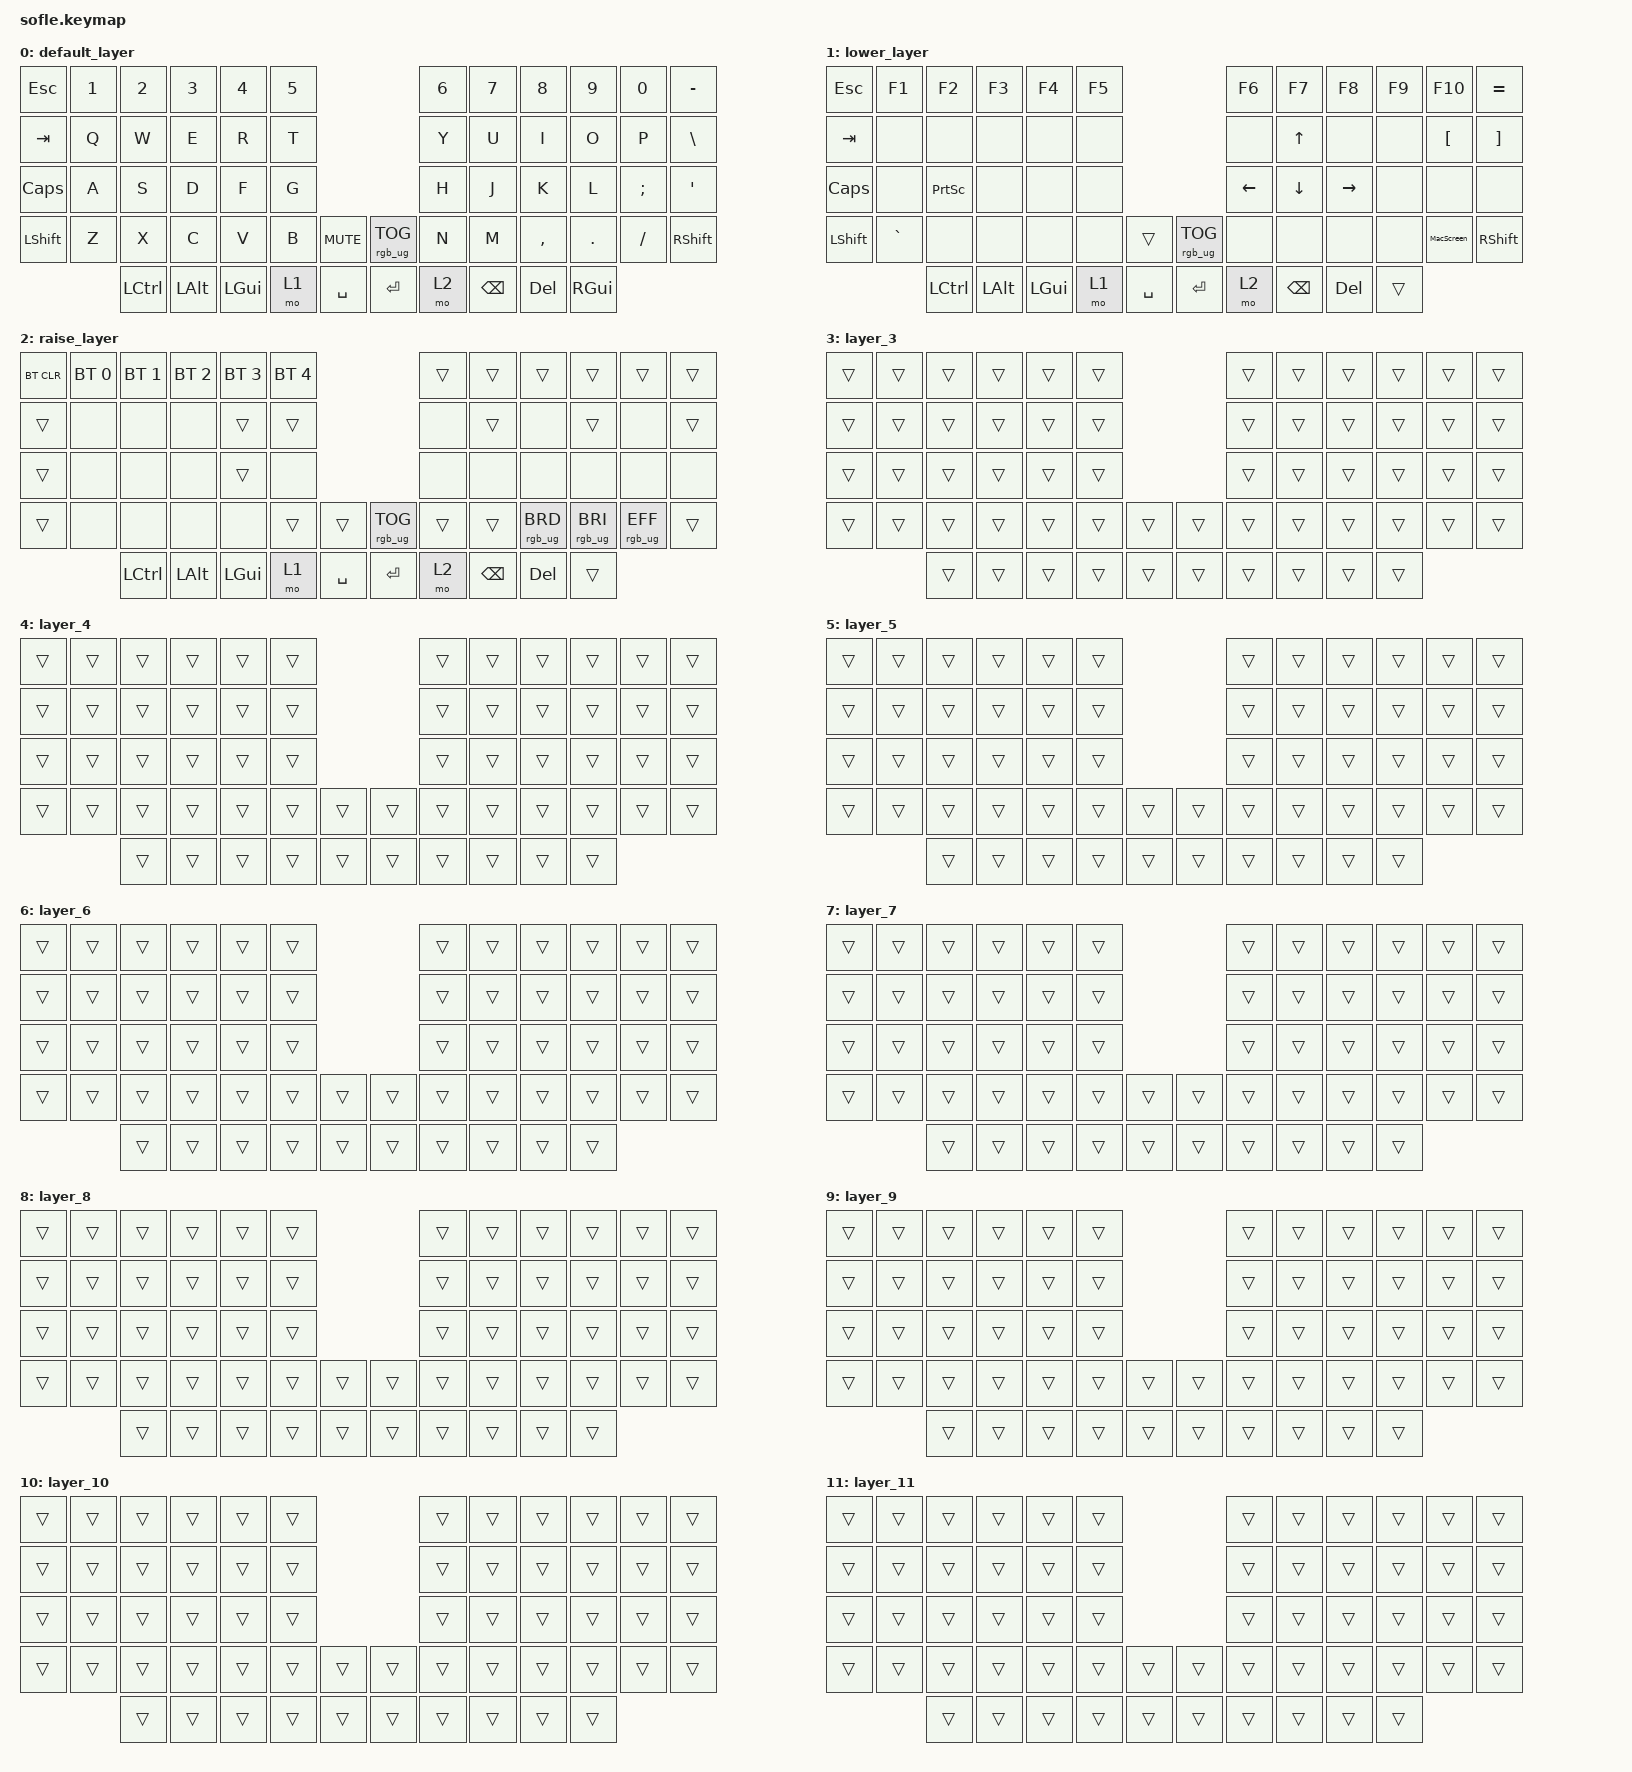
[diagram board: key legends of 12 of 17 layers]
/*
 * Copyright (c) 2020 The ZMK Contributors
 *
 * SPDX-License-Identifier: MIT
 */
/*
 * Temporarily here because nice nano v2 spi is not defined on ZMK Yet
 * Source: https://github.com/zmkfirmware/zmk/blob/main/app/boards/shields/reviung41/boards/nice_nano.overlay
 * GitHub Issue: https://github.com/zmkfirmware/zmk/issues/885
 */

#include <dt-bindings/led/led.h>
#include <behaviors.dtsi>
#include <dt-bindings/zmk/bt.h>
#include <dt-bindings/zmk/keys.h>
#include <dt-bindings/zmk/rgb.h>

&pinctrl {
    spi3_default: spi3_default {
        group1 { psels = <NRF_PSEL(SPIM_MOSI, 0, 8)>; };
    };

    spi3_sleep: spi3_sleep {
        group1 {
            psels = <NRF_PSEL(SPIM_MOSI, 0, 8)>;
            low-power-enable;
        };
    };
};

&spi3 {
    compatible = "nordic,nrf-spim";
    status = "okay";
    pinctrl-0 = <&spi3_default>;
    pinctrl-1 = <&spi3_sleep>;
    pinctrl-names = "default", "sleep";

    led_strip: ws2812@0 {
        compatible = "worldsemi,ws2812-spi";
        label = "WS2812";

        /* SPI */

        reg = <0>; /* ignored, but necessary for SPI bindings */
        spi-max-frequency = <4000000>;

        /* WS2812 */

        chain-length = <30>;
        spi-one-frame = <0x70>;
        spi-zero-frame = <0x40>;
        color-mapping = <LED_COLOR_ID_GREEN LED_COLOR_ID_RED LED_COLOR_ID_BLUE>;
    };
};

/ {
    chosen { zmk,underglow = &led_strip; };
};

/* END temporary RGB support section */

/ {
    macros {
        MacScreen: MacScreen {
            compatible = "zmk,behavior-macro";
            #binding-cells = <0>;
            bindings = <&kp LSHFT &kp LCTRL &kp LGUI &kp KP_NUMBER_4>;
            label = "MACSCREEN";
        };
    };

    keymap {
        compatible = "zmk,keymap";

        default_layer {
            // ------------------------------------------------------------------------------------------------------------------
            // |  `    |  1  |  2  |  3   |  4   |  5   |                         |  6   |  7    |  8    |  9   |   0   |       |
            // |  ESC  |  Q  |  W  |  E   |  R   |  T   |                         |  Y   |  U    |  I    |  O   |   P   | BKSPC |
            // |  TAB  |  A  |  S  |  D   |  F   |  G   |                         |  H   |  J    |  K    |  L   |   ;   |   '   |
            // | SHIFT |  Z  |  X  |  C   |  V   |  B   |  MUTE  |        | ExtPw |  N   |  M    |  ,    |  .   |   /   | SHIFT |
            //               | GUI | ALT  | CTRL | LOWER|  ENTER |        | SPACE | RAISE| CTRL  | ALT   | GUI  |

            bindings = <
&kp ESCAPE  &kp N1  &kp N2     &kp N3    &kp N4    &kp N5                                 &kp N6  &kp N7         &kp N8     &kp N9    &kp N0    &kp MINUS
&kp TAB     &kp Q   &kp W      &kp E     &kp R     &kp T                                  &kp Y   &kp U          &kp I      &kp O     &kp P     &kp BACKSLASH
&kp CLCK    &kp A   &kp S      &kp D     &kp F     &kp G                                  &kp H   &kp J          &kp K      &kp L     &kp SEMI  &kp SQT
&kp LSHFT   &kp Z   &kp X      &kp C     &kp V     &kp B   &kp C_MUTE    &rgb_ug RGB_TOG  &kp N   &kp M          &kp COMMA  &kp DOT   &kp FSLH  &kp RSHFT
                    &kp LCTRL  &kp LALT  &kp LGUI  &mo 1   &kp SPACE     &kp ENTER        &mo 2   &kp BACKSPACE  &kp DEL    &kp RGUI
            >;

            sensor-bindings = <&inc_dec_kp C_VOL_UP C_VOL_DN &inc_dec_kp PG_UP PG_DN>;
        };

        lower_layer {
            // TODO: Some binds are waiting for shifted keycode support.
            // ------------------------------------------------------------------------------------------------------------
            // |       |  F1 |  F2 |  F3  |  F4  |  F5  |                   |  F6  |  F7   |  F8   |  F9  |  F10  |  F11  |
            // | `     |   1 |   2 |   3  |   4  |   5  |                   |   6  |   7   |   8   |   9  |    0  |  F12  |
            // |       |  !  |  @  |  #   |  $   |  %   |                   |  ^   |  &    |  *    |  (   |   )   |   |   |
            // |       |  =  |  -  |  +   |  {   |  }   |        |  |       |  [   |  ]    |  ;    |  :   |   \   |       |
            //               |     |      |      |      |        |  |       |      |       |       |      |

            bindings = <
&kp ESCAPE  &kp F1     &kp F2           &kp F3    &kp F4    &kp F5                                &kp F6          &kp F7          &kp F8           &kp F9  &kp F10           &kp EQUAL
&kp TAB     &none      &none            &none     &none     &none                                 &none           &kp UP_ARROW    &none            &none   &kp LEFT_BRACKET  &kp RIGHT_BRACKET
&kp CLCK    &none      &kp PRINTSCREEN  &none     &none     &none                                 &kp LEFT_ARROW  &kp DOWN_ARROW  &kp RIGHT_ARROW  &none   &none             &none
&kp LSHFT   &kp GRAVE  &none            &none     &none     &none   &trans       &rgb_ug RGB_TOG  &none           &none           &none            &none   &MacScreen        &kp RSHFT
                       &kp LCTRL        &kp LALT  &kp LGUI  &mo 1   &kp SPACE    &kp ENTER        &mo 2           &kp BACKSPACE   &kp DEL          &trans
            >;

            sensor-bindings = <&inc_dec_kp C_VOL_UP C_VOL_DN &inc_dec_kp PG_UP PG_DN>;
        };

        raise_layer {
            // ------------------------------------------------------------------------------------------------------------
            // |BTCLR| BT1  | BT2  |  BT3  |  BT4  |  BT5 |                 |      |      |       |      |       |       |
            // |     | INS  | PSCR | GUI   |       |      |                 | PGUP |      |   ^   |      |       |       |
            // |     | ALT  | CTRL | SHIFT |       | CAPS |                 | PGDN |   <- |   v   |  ->  |  DEL  | BKSPC |
            // |     | UNDO | CUT  | COPY  | PASTE |      |      |   | RGB  |      |      |       |      |       |       |
            //              |      |       |       |      |      |   |      |      |      |       |      |

            bindings = <
&bt BT_CLR  &bt BT_SEL 0  &bt BT_SEL 1  &bt BT_SEL 2  &bt BT_SEL 3  &bt BT_SEL 4                                &trans  &trans         &trans           &trans           &trans           &trans
&trans      &none         &none         &none         &trans        &trans                                      &none   &trans         &none            &trans           &none            &trans
&trans      &none         &none         &none         &trans        &none                                       &none   &none          &none            &none            &none            &none
&trans      &none         &none         &none         &none         &trans        &trans       &rgb_ug RGB_TOG  &trans  &trans         &rgb_ug RGB_BRD  &rgb_ug RGB_BRI  &rgb_ug RGB_EFF  &trans
                          &kp LCTRL     &kp LALT      &kp LGUI      &mo 1         &kp SPACE    &kp ENTER        &mo 2   &kp BACKSPACE  &kp DEL          &trans
            >;

            sensor-bindings = <&inc_dec_kp C_VOL_UP C_VOL_DN &inc_dec_kp PG_UP PG_DN>;
        };

        layer_3 {
            bindings = <
&trans  &trans  &trans  &trans  &trans  &trans                    &trans  &trans  &trans  &trans  &trans  &trans
&trans  &trans  &trans  &trans  &trans  &trans                    &trans  &trans  &trans  &trans  &trans  &trans
&trans  &trans  &trans  &trans  &trans  &trans                    &trans  &trans  &trans  &trans  &trans  &trans
&trans  &trans  &trans  &trans  &trans  &trans  &trans    &trans  &trans  &trans  &trans  &trans  &trans  &trans
                &trans  &trans  &trans  &trans  &trans    &trans  &trans  &trans  &trans  &trans
            >;
        };

        layer_4 {
            bindings = <
&trans  &trans  &trans  &trans  &trans  &trans                    &trans  &trans  &trans  &trans  &trans  &trans
&trans  &trans  &trans  &trans  &trans  &trans                    &trans  &trans  &trans  &trans  &trans  &trans
&trans  &trans  &trans  &trans  &trans  &trans                    &trans  &trans  &trans  &trans  &trans  &trans
&trans  &trans  &trans  &trans  &trans  &trans  &trans    &trans  &trans  &trans  &trans  &trans  &trans  &trans
                &trans  &trans  &trans  &trans  &trans    &trans  &trans  &trans  &trans  &trans
            >;
        };

        layer_5 {
            bindings = <
&trans  &trans  &trans  &trans  &trans  &trans                    &trans  &trans  &trans  &trans  &trans  &trans
&trans  &trans  &trans  &trans  &trans  &trans                    &trans  &trans  &trans  &trans  &trans  &trans
&trans  &trans  &trans  &trans  &trans  &trans                    &trans  &trans  &trans  &trans  &trans  &trans
&trans  &trans  &trans  &trans  &trans  &trans  &trans    &trans  &trans  &trans  &trans  &trans  &trans  &trans
                &trans  &trans  &trans  &trans  &trans    &trans  &trans  &trans  &trans  &trans
            >;
        };

        layer_6 {
            bindings = <
&trans  &trans  &trans  &trans  &trans  &trans                    &trans  &trans  &trans  &trans  &trans  &trans
&trans  &trans  &trans  &trans  &trans  &trans                    &trans  &trans  &trans  &trans  &trans  &trans
&trans  &trans  &trans  &trans  &trans  &trans                    &trans  &trans  &trans  &trans  &trans  &trans
&trans  &trans  &trans  &trans  &trans  &trans  &trans    &trans  &trans  &trans  &trans  &trans  &trans  &trans
                &trans  &trans  &trans  &trans  &trans    &trans  &trans  &trans  &trans  &trans
            >;
        };

        layer_7 {
            bindings = <
&trans  &trans  &trans  &trans  &trans  &trans                    &trans  &trans  &trans  &trans  &trans  &trans
&trans  &trans  &trans  &trans  &trans  &trans                    &trans  &trans  &trans  &trans  &trans  &trans
&trans  &trans  &trans  &trans  &trans  &trans                    &trans  &trans  &trans  &trans  &trans  &trans
&trans  &trans  &trans  &trans  &trans  &trans  &trans    &trans  &trans  &trans  &trans  &trans  &trans  &trans
                &trans  &trans  &trans  &trans  &trans    &trans  &trans  &trans  &trans  &trans
            >;
        };

        layer_8 {
            bindings = <
&trans  &trans  &trans  &trans  &trans  &trans                    &trans  &trans  &trans  &trans  &trans  &trans
&trans  &trans  &trans  &trans  &trans  &trans                    &trans  &trans  &trans  &trans  &trans  &trans
&trans  &trans  &trans  &trans  &trans  &trans                    &trans  &trans  &trans  &trans  &trans  &trans
&trans  &trans  &trans  &trans  &trans  &trans  &trans    &trans  &trans  &trans  &trans  &trans  &trans  &trans
                &trans  &trans  &trans  &trans  &trans    &trans  &trans  &trans  &trans  &trans
            >;
        };

        layer_9 {
            bindings = <
&trans  &trans  &trans  &trans  &trans  &trans                    &trans  &trans  &trans  &trans  &trans  &trans
&trans  &trans  &trans  &trans  &trans  &trans                    &trans  &trans  &trans  &trans  &trans  &trans
&trans  &trans  &trans  &trans  &trans  &trans                    &trans  &trans  &trans  &trans  &trans  &trans
&trans  &trans  &trans  &trans  &trans  &trans  &trans    &trans  &trans  &trans  &trans  &trans  &trans  &trans
                &trans  &trans  &trans  &trans  &trans    &trans  &trans  &trans  &trans  &trans
            >;
        };

        layer_10 {
            bindings = <
&trans  &trans  &trans  &trans  &trans  &trans                    &trans  &trans  &trans  &trans  &trans  &trans
&trans  &trans  &trans  &trans  &trans  &trans                    &trans  &trans  &trans  &trans  &trans  &trans
&trans  &trans  &trans  &trans  &trans  &trans                    &trans  &trans  &trans  &trans  &trans  &trans
&trans  &trans  &trans  &trans  &trans  &trans  &trans    &trans  &trans  &trans  &trans  &trans  &trans  &trans
                &trans  &trans  &trans  &trans  &trans    &trans  &trans  &trans  &trans  &trans
            >;
        };

        layer_11 {
            bindings = <
&trans  &trans  &trans  &trans  &trans  &trans                    &trans  &trans  &trans  &trans  &trans  &trans
&trans  &trans  &trans  &trans  &trans  &trans                    &trans  &trans  &trans  &trans  &trans  &trans
&trans  &trans  &trans  &trans  &trans  &trans                    &trans  &trans  &trans  &trans  &trans  &trans
&trans  &trans  &trans  &trans  &trans  &trans  &trans    &trans  &trans  &trans  &trans  &trans  &trans  &trans
                &trans  &trans  &trans  &trans  &trans    &trans  &trans  &trans  &trans  &trans
            >;
        };

        layer_12 {
            bindings = <
&trans  &trans  &trans  &trans  &trans  &trans                    &trans  &trans  &trans  &trans  &trans  &trans
&trans  &trans  &trans  &trans  &trans  &trans                    &trans  &trans  &trans  &trans  &trans  &trans
&trans  &trans  &trans  &trans  &trans  &trans                    &trans  &trans  &trans  &trans  &trans  &trans
&trans  &trans  &trans  &trans  &trans  &trans  &trans    &trans  &trans  &trans  &trans  &trans  &trans  &trans
                &trans  &trans  &trans  &trans  &trans    &trans  &trans  &trans  &trans  &trans
            >;
        };

        layer_13 {
            bindings = <
&trans  &trans  &trans  &trans  &trans  &trans                    &trans  &trans  &trans  &trans  &trans  &trans
&trans  &trans  &trans  &trans  &trans  &trans                    &trans  &trans  &trans  &trans  &trans  &trans
&trans  &trans  &trans  &trans  &trans  &trans                    &trans  &trans  &trans  &trans  &trans  &trans
&trans  &trans  &trans  &trans  &trans  &trans  &trans    &trans  &trans  &trans  &trans  &trans  &trans  &trans
                &trans  &trans  &trans  &trans  &trans    &trans  &trans  &trans  &trans  &trans
            >;
        };

        layer_14 {
            bindings = <
&trans  &trans  &trans  &trans  &trans  &trans                    &trans  &trans  &trans  &trans  &trans  &trans
&trans  &trans  &trans  &trans  &trans  &trans                    &trans  &trans  &trans  &trans  &trans  &trans
&trans  &trans  &trans  &trans  &trans  &trans                    &trans  &trans  &trans  &trans  &trans  &trans
&trans  &trans  &trans  &trans  &trans  &trans  &trans    &trans  &trans  &trans  &trans  &trans  &trans  &trans
                &trans  &trans  &trans  &trans  &trans    &trans  &trans  &trans  &trans  &trans
            >;
        };

        layer_15 {
            bindings = <
&trans  &trans  &trans  &trans  &trans  &trans                    &trans  &trans  &trans  &trans  &trans  &trans
&trans  &trans  &trans  &trans  &trans  &trans                    &trans  &trans  &trans  &trans  &trans  &trans
&trans  &trans  &trans  &trans  &trans  &trans                    &trans  &trans  &trans  &trans  &trans  &trans
&trans  &trans  &trans  &trans  &trans  &trans  &trans    &trans  &trans  &trans  &trans  &trans  &trans  &trans
                &trans  &trans  &trans  &trans  &trans    &trans  &trans  &trans  &trans  &trans
            >;
        };

        layer_16 {
            bindings = <
&trans  &trans  &trans  &trans  &trans  &trans                    &trans  &trans  &trans  &trans  &trans  &trans
&trans  &trans  &trans  &trans  &trans  &trans                    &trans  &trans  &trans  &trans  &trans  &trans
&trans  &trans  &trans  &trans  &trans  &trans                    &trans  &trans  &trans  &trans  &trans  &trans
&trans  &trans  &trans  &trans  &trans  &trans  &trans    &trans  &trans  &trans  &trans  &trans  &trans  &trans
                &trans  &trans  &trans  &trans  &trans    &trans  &trans  &trans  &trans  &trans
            >;
        };
    };
};
